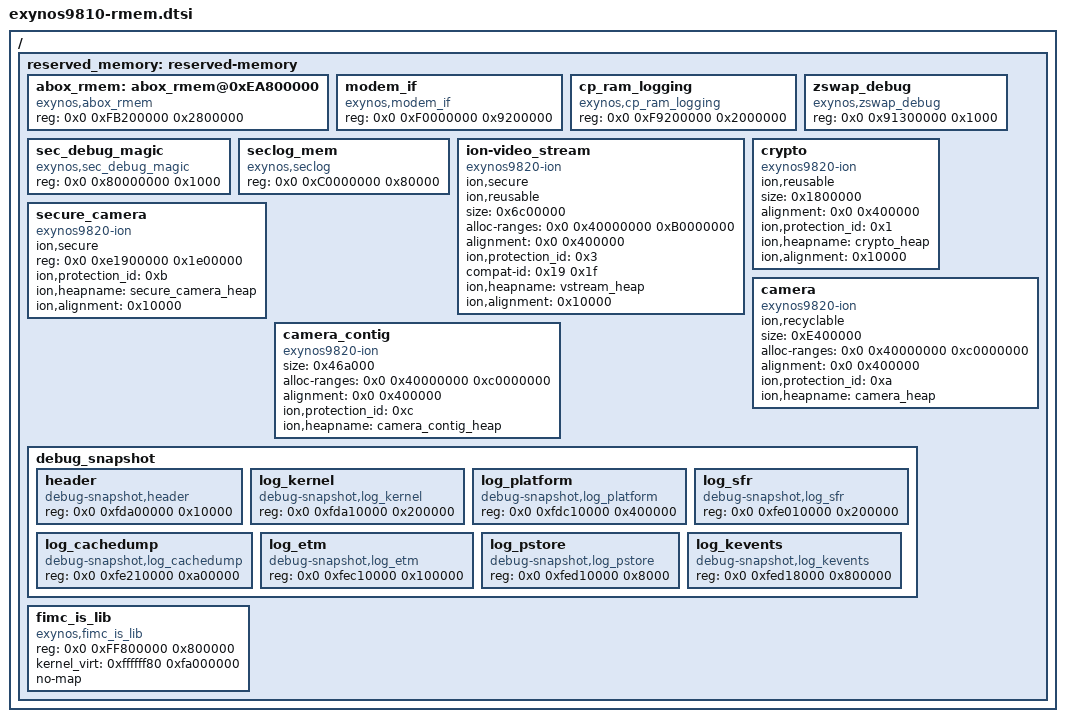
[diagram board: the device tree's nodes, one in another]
/*
 * SAMSUNG EXYNOS device tree source for reserved-memory
 *
 * Copyright (c) 2015 Samsung Electronics Co., Ltd.
 *		http://www.samsung.com
 *
 * This program is free software; you can redistribute it and/or modify
 * it under the terms of the GNU General Public License version 2 as
 * published by the Free Software Foundation.
 */

#include "../../../../../out/include/generated/autoconf.h"

/ {
	reserved_memory: reserved-memory {
		#address-cells = <2>;
		#size-cells = <1>;
		ranges;

		abox_rmem: abox_rmem@0xEA800000 {
			compatible = "exynos,abox_rmem";
			reg = <0x0 0xFB200000 0x2800000>;
		};

		modem_if {
			compatible = "exynos,modem_if";
			reg = <0x0 0xF0000000 0x9200000>;
		};

		cp_ram_logging {
			compatible = "exynos,cp_ram_logging";
			reg = <0x0 0xF9200000 0x2000000>;
		};

		zswap_debug {
			compatible = "exynos,zswap_debug";
			reg = <0x0 0x91300000 0x1000>;
		};

		sec_debug_magic {
			compatible = "exynos,sec_debug_magic";
			reg = <0x0 0x80000000 0x1000>;
		};

		seclog_mem {
			compatible = "exynos,seclog";
			reg = <0x0 0xC0000000 0x80000>;
		};

		ion-video_stream {
			compatible = "exynos9820-ion";
			ion,secure;
			ion,reusable;
			size = <0x6c00000>;
			alloc-ranges = <0x0 0x40000000 0xB0000000>;
			alignment = <0x0 0x400000>;
			ion,protection_id = <0x3>;
			compat-id = <0x19 0x1f>;
			ion,heapname = "vstream_heap";
			ion,alignment = <0x10000>;
		};

		crypto {
			compatible = "exynos9820-ion";
			ion,reusable;
			size = <0x1800000>;
			alignment = <0x0 0x400000>;
			ion,protection_id = <0x1>;
			ion,heapname = "crypto_heap";
			ion,alignment = <0x10000>;
		};

		secure_camera {
			compatible = "exynos9820-ion";
			ion,secure;
			reg = <0x0 0xe1900000 0x1e00000>;
			ion,protection_id = <0xb>;
			ion,heapname = "secure_camera_heap";
			ion,alignment = <0x10000>;
		};

		camera {
			compatible = "exynos9820-ion";
			ion,recyclable;
			size = <0xE400000>;
			alloc-ranges = <0x0 0x40000000 0xc0000000>;
			alignment = <0x0 0x400000>;
			ion,protection_id = <0xa>;
			ion,heapname = "camera_heap";
		};

		camera_contig {
			compatible = "exynos9820-ion";
			size = <0x46a000>;
			alloc-ranges = <0x0 0x40000000 0xc0000000>;
			alignment = <0x0 0x400000>;
			ion,protection_id = <0xc>;
			ion,heapname = "camera_contig_heap";
		};

		debug_snapshot {
			#address-cells = <0x2>;
			#size-cells = <0x1>;

			header {
				compatible = "debug-snapshot,header";
				reg = <0x0 0xfda00000 0x10000>;
			};

			log_kernel {
				compatible = "debug-snapshot,log_kernel";
				reg = <0x0 0xfda10000 0x200000>;
			};

			log_platform {
				compatible = "debug-snapshot,log_platform";
				reg = <0x0 0xfdc10000 0x400000>;
			};

			log_sfr {
				compatible = "debug-snapshot,log_sfr";
				reg = <0x0 0xfe010000 0x200000>;
			};

			log_cachedump {
				compatible = "debug-snapshot,log_cachedump";
				reg = <0x0 0xfe210000 0xa00000>;
			};

			log_etm {
				compatible = "debug-snapshot,log_etm";
				reg = <0x0 0xfec10000 0x100000>;
			};

			log_pstore {
				compatible = "debug-snapshot,log_pstore";
				reg = <0x0 0xfed10000 0x8000>;
			};

			log_kevents {
				compatible = "debug-snapshot,log_kevents";
				reg = <0x0 0xfed18000 0x800000>;
			};
		};

		fimc_is_lib {
			compatible = "exynos,fimc_is_lib";
			reg = <0x0 0xFF800000 0x800000>;
			kernel_virt = <0xffffff80 0xfa000000>;
			no-map;
		};
	};
};
